# MCU_NAVSS0_RINGACC0_UDMASS_RINGACC0_CFG register map
Vendor: Texas Instruments
Peripheral module from a debugger description file (folder J7_AHP).
Registers are 32-bit, read-write, reset 0x0 unless marked. A register's access mark holds for its fields unless they carry their own. Offsets are as the file gives them; lines under a group give offsets from that group; [hi:lo] are bit positions; {n}, {i} and the like mark numbered series; 'fields as' and 'values as' point back to an identical list; <NAME> marks a mode.

## MCU_NAVSS0_RINGACC0_UDMASS_RINGACC0_CFG
0x40 PAR_UDMASS__RINGACC0_CFG__CFG_BA_LO
  [31:0] ADDR_LO — Tx Ring base address (LSBs)
0x44 PAR_UDMASS__RINGACC0_CFG__CFG_BA_HI
  [15:0] ADDR_HI — Tx Ring base address (MSBs)
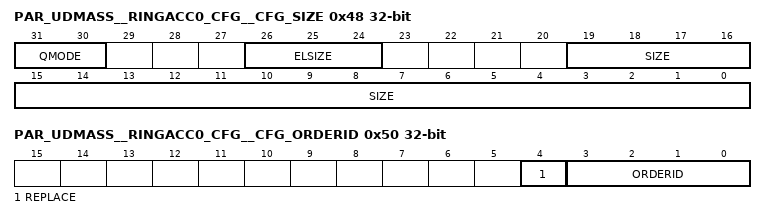
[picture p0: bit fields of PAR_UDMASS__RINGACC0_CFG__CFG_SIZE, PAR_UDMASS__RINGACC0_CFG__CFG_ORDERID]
0x48 PAR_UDMASS__RINGACC0_CFG__CFG_SIZE
  [31:30] QMODE — Defines the mode for this ring or queue.
  [26:24] ELSIZE — Ring element size. This field is encoded as follows: 0 = 4 bytes 1 = 8 bytes 2 = 16 bytes 3 = 32 bytes 4 = 64 bytes 5 = 128 bytes 6 = 256 bytes 7 = RESERVED
  [19:0] SIZE — Tx Ring element count. This field configures the size of the ring in elements. For rings in CREDENTIALS or QM modes the size must be an even number.
0x4C PAR_UDMASS__RINGACC0_CFG__CFG_EVT reset 0xFFFF
  [15:0] EVT — Defines the event for this ring or queue.
0x50 PAR_UDMASS__RINGACC0_CFG__CFG_ORDERID
  [4] REPLACE — Indicates to replace the bus orderid value for this ring or queue with the orderid MMR field. This allows control over the orderid value when it must be restricted due to the topology for QoS reasons. 0 = bypass and use the orderid from the source transaction for the destination transaction. 1 = use the orderid MMR field value for the destination transaction.
  [3:0] ORDERID — Defines the bus orderid value for this ring or queue.
